# K1921VK01T register map
Vendor: NIIET; Series: K1921VKx; File version: 2.2
CPU: CM4 r0p1, little endian, MPU, FPU, 3 interrupt priority bits
Registers are 32-bit, read-write, reset 0x0 unless marked. A register's access mark holds for its fields unless they carry their own. Offsets are from the block's base; [hi:lo] are bit positions; {n}, {i} and the like mark numbered series; 'fields as' and 'values as' point back to an identical list.

## NT_BOOTFLASH — BOOTFLASH controller registers
Base 0xA001C000
0x00 FMA — Address bootflash register
  [19:0] ADDR
0x04 FMD0 — Data words bootable flash register 0
  [31:0] DATA0
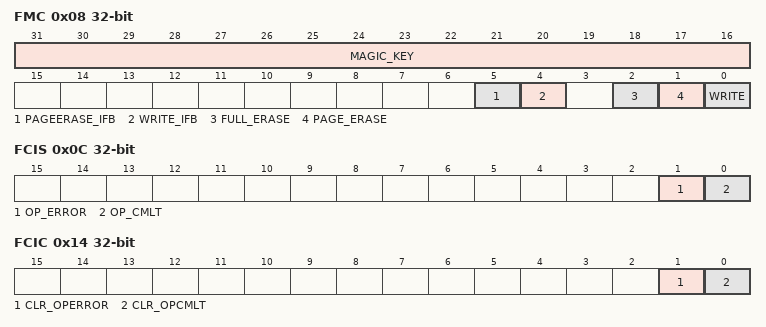
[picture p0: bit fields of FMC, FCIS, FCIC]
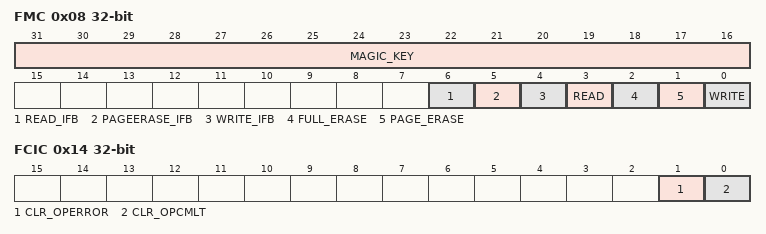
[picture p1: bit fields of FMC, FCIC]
0x08 FMC wo — Command register
  [31:16] MAGIC_KEY
  [5] PAGEERASE_IFB — Bit erase page of information block
  [4] WRITE_IFB — Bit writing on information block
  [2] FULL_ERASE — Bit erase main block
  [1] PAGE_ERASE — Bit paged erase the main block
  [0] WRITE — Bit writing in main block
0x0C FCIS ro — Status register
  [1] OP_ERROR — Flag write error, erase block write-protected or non-existent, or read from a non-existent block
  [0] OP_CMLT — Completion flag operation
0x10 FCIM — Interrupt mask register
  [0] MASK_OPCMLT — Enables generation of an interrupt upon completion of a read or write, or erase
0x14 FCIC wo — Command register
  [1] CLR_OPERROR — Clear flag operate Error
  [0] CLR_OPCMLT — Clear flag operate complit
{0x4C+4i} FMD{i} (i=1..3) — Data words bootable flash register {i}
  [31:0] DATA{i}
0x80 T_ACC — Register the delay of setting addresses to read data from the flash memory
0x84 T_NVS — Register signal delay lifting NVSTR after lifting signal PROG
0x88 T_NVH — Register sets the release delay signal NVSTR after releasing signal PROG
0x8C T_RCV — Register delay from releasing signal NVSTR to raise it to the next transaction
0x90 T_PGS — Register delay lifting signal YE after lifting signal NVSTR
0x94 T_PROG — Register YE signal duration in recording transactions
0x98 T_PGH — Register delay signal NVSTR after releasing signal YE
0x9C T_ERASE — Register duration of the signal in transactions ERASE erasure
0xA0 T_ME — Register specifies the duration of the signal in transactions ERASE erasure
0xA4 T_NVH1 — Register specifies the duration of the signal in transactions ERASE erasure

## NT_USERFLASH — USERFLASH controller registers
Base 0xA0022000
Registers as NT_BOOTFLASH, without FMD{n} (n=0..3); these are added or differ:
0x00 FMA — Address userflash register
  [15:0] ADDR — Address for commands write and page erase
0x04 FMD — Data byte user flash register
  [7:0] DATA — User flash data
0x08 FMC wo — Command register
  [31:16] MAGIC_KEY — Code run command. For activate command in MAGIC_KEY write 0xA442
  [6] READ_IFB
  [5] PAGEERASE_IFB — Bit erase page of information block
  [4] WRITE_IFB — Bit writing on information block
  [3] READ
  [2] FULL_ERASE — Bit erase main block
  [1] PAGE_ERASE — Bit paged erase the main block
  [0] WRITE — Bit writing in main block
0x14 FCIC wo — Clear status register
  [1] CLR_OPERROR — Clear flag operate Error
  [0] CLR_OPCMLT — Clear flag operate complit

## NT_CMP — CMP controller registers
Base 0xA001D000
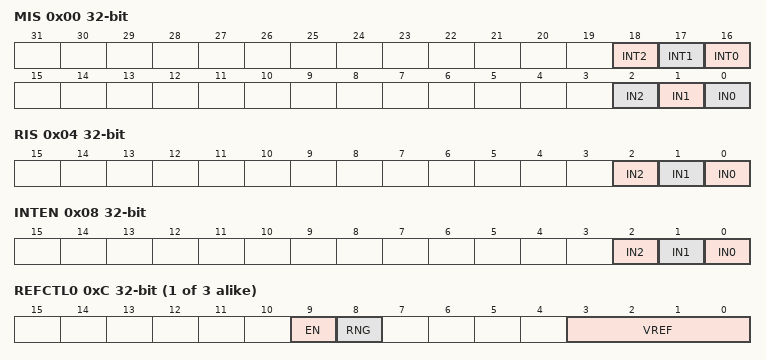
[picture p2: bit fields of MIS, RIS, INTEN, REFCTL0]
0x00 MIS — Masked interrupt status register
  [18] INT2 — reset get interrupt CMP2
  [17] INT1 — reset get interrupt CMP1
  [16] INT0 — reset get interrupt CMP0
  [2] IN2 — reset interrupt status CMP2
  [1] IN1 — reset interrupt status CMP1
  [0] IN0 — reset interrupt status CMP0
0x04 RIS ro — Interrupt Status Register
  [2] IN2 — set interrupt status CMP2
  [1] IN1 — set interrupt status CMP1
  [0] IN0 — set interrupt status CMP0
0x08 INTEN — Interrupt mask register
  [2] IN2 — Mask interrupt CMP2
  [1] IN1 — Mask interrupt CMP1
  [0] IN0 — Mask interrupt CMP0
{0xC+4i} REFCTL{i} (i=0..2) — Reference voltage control DAC{i} register
  [9] EN — power to the built-in DAC
  [8] RNG — range of the DAC
  [3:0] VREF
{0x20+0x20*i} STAT{i} ro (i=0..2) — Status register CMP{i}
  [1] OVAL — output value of the comparator{i}
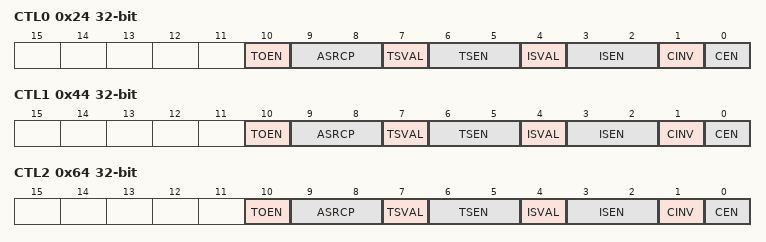
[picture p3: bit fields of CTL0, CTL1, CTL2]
0x24 CTL0 — Control Register CMP0
  [10] TOEN — ADC start generating events
  [9:8] ASRCP
    0=C0Plus (pin C0+ connected as comparator 0 + in); 1=C1Plus (pin C1+ connected as comparator 0 + in); 2=DAC0 (DAC 0 out connected as comparator 0 + in)
  [7] TSVAL — ADC start at a low level
  [6:5] TSEN
    0=LvlISVAL (interrupt on level depended of IVAL state); 1=PosEdge (interrupt on posedge); 2=NegEdge (interrupt on negedge); 3=EveryEdge (interrupt on posedge and negedge)
  [4] ISVAL — interrupt on a low level
  [3:2] ISEN
  [1] CINV — polarity of output signal
  [0] CEN — enable compare 0
0x44 CTL1 — Control Register CMP1
  [10] TOEN — ADC start generating events
  [9:8] ASRCP
    0=C1Plus (pin C1+ connected as comparator 1 + in); 2=DAC1 (DAC 1 out connected as comparator 1 + in); 3=DAC0 (DAC 0 out connected as comparator 1 + in)
  [7] TSVAL — ADC start at a low level
    values as ASRCP
  [6:5] TSEN
    values as CTL0.TSEN
  [4] ISVAL — interrupt on a low level
  [3:2] ISEN
  [1] CINV — polarity of output signal
  [0] CEN — enable compare 1
0x64 CTL2 — Control Register CMP2
  [10] TOEN — ADC start generating events
  [9:8] ASRCP
    0=C2Plus (pin C2+ connected as comparator 2 + in); 1=C1Plus (pin C1+ connected as comparator 2 + in); 2=DAC2 (DAC 2 out connected as comparator 2 + in); 3=DAC0 (DAC 0 out connected as comparator 2 + in)
  [7] TSVAL — ADC start at a low level
    values as ASRCP
  [6:5] TSEN
    values as CTL0.TSEN
  [4] ISVAL — interrupt on a low level
  [3:2] ISEN
  [1] CINV — polarity of output signal
  [0] CEN — enable compare 2
0x7C POWER — Power analog circuits register
  [0] PWU — Enable power analog circuits

## NT_SPI0 — SPI controller registers
Base 0xA001E000
Same registers: NT_SPI1 0xA001F000, NT_SPI2 0xA0020000, NT_SPI3 0xA0021000
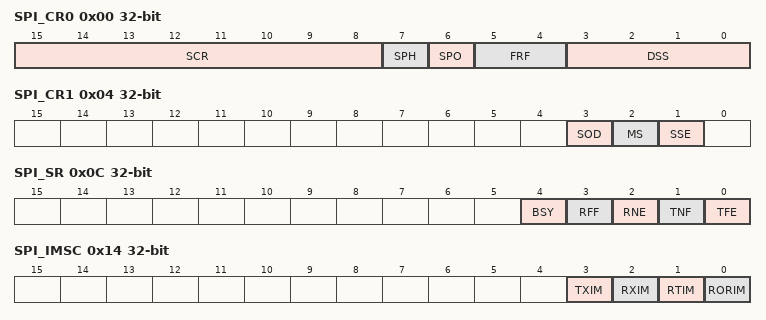
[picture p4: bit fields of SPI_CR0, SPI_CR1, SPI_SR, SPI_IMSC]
0x00 SPI_CR0 — Control register 0
  [15:8] SCR
  [7] SPH — Phase SSPCLKOUT
  [6] SPO — Polarity SSPCLKOUT
  [5:4] FRF
    0=SPI (SPI of Motorola); 1=SSI (SSI of Texas Instruments); 2=Microwire of National Semiconductor
  [3:0] DSS
    {v}={v+1}bit (data size {v+1} bit) (v=3..15)
0x04 SPI_CR1 — Control register 1
  [3] SOD — Disable bit data
  [2] MS — Select mode
  [1] SSE — Enable transceiver
0x08 SPI_DR — Data register
  [15:0] DATA
0x0C SPI_SR ro — State register
  [4] BSY — Activity flag
  [3] RFF — Indicate full receive buffer
  [2] RNE — Indicate not empty receive buffer
  [1] TNF — Indicator the transmitter FIFO buffer is not full
  [0] TFE — FIFO buffer empty flag transmitter
0x10 SPI_CPSR — Clock division factor register
  [7:0] CPSDVSR ro
0x14 SPI_IMSC — Mask interrupt register
  [3] TXIM — SSPTXINTR interrupt mask bit to fill 50% or less of the FIFO buffer of the transmitter
  [2] RXIM — SSPRXINTR interrupt mask bit to fill 50% or less of the receiver FIFO buffer
  [1] RTIM — Interrupt mask bit SSPRTINTR timeout receiver
  [0] RORIM — Interrupt mask bit SSPRORINTR buffer overflow receiver
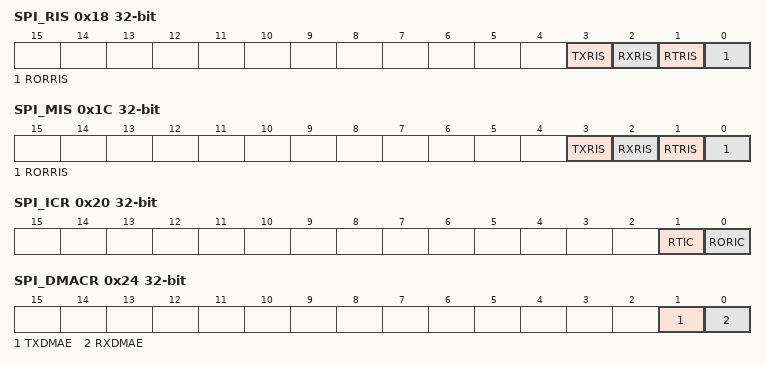
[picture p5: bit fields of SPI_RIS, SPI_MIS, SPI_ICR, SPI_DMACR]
0x18 SPI_RIS ro — Status register interrupt without mask
  [3] TXRIS — Interrupt status before masking SSPTXINTR
  [2] RXRIS — Interrupt status before masking SSPRXINTR
  [1] RTRIS — Interrupt status before masking SSPRTINTR
  [0] RORRIS — Interrupt status before masking SSPRORINTR
0x1C SPI_MIS ro — Status register interrupt masking account
  [3] TXRIS — Masked interrupt status SSPTXINTR
  [2] RXRIS — Masked interrupt status SSPRXINTR
  [1] RTRIS — Masked interrupt status SSPRTINTR
  [0] RORRIS — Masked interrupt status SSPRORINTR
0x20 SPI_ICR wo — Register reset interrupt
  [1] RTIC — Reset interrupt SSPRTINTR
  [0] RORIC — Reset interrupt SSPRORINTR
0x24 SPI_DMACR — Control register DMA
  [1] TXDMAE — DMA enable bit transmission
  [0] RXDMAE — DMA enable bit at reception

## NT_RTC — RTC controller registers
Base 0xA0023000
0x00 PSECONDS — Part seconds register
  [9:0] PART_SEC
0x04 SECOND — Seconds register
  [6:0] SECOND
0x08 MINUTE
  [6:0] MINUTE
0x10 HOUR
  [5:0] HOUR — Hours in BCD format
0x18 WDAY — Day of week register
  [2:0] DAYWEEK
0x20 DAY
  [5:0] DAY — Day in BCD format
0x24 MONTH
  [4:0] MONTH
0x28 YEAR
  [7:0] YEAR
0x2C SHDW wo — Register Update shadow registers RTC
  [7] UPDTEN — Enable update shadow registers RTC
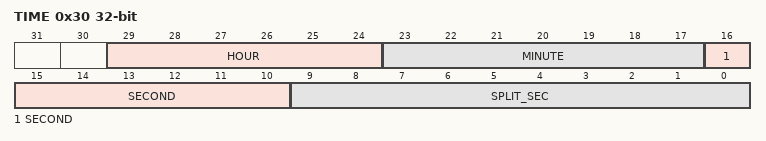
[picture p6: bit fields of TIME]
0x30 TIME ro — General register Time
  [29:24] HOUR, [23:17] MINUTE, [16:10] SECOND, [9:0] SPLIT_SEC
